# MB9BF46xx register map
File version: 1.0
Registers are 8-bit, read-write, reset 0x0 unless marked. A register's access mark holds for its fields unless they carry their own. Offsets are from the block's base; [hi:lo] are bit positions; 'fields as' and 'values as' point back to an identical list.

## WORKFLASH_IF — peripheral WORKFLASH_IF
Base 0x200E0000
0x00 WFASZR 32-bit reset 0x1
  [0] ASZ
0x04 WFRWTR 32-bit reset 0x4
  [2:0] RWT
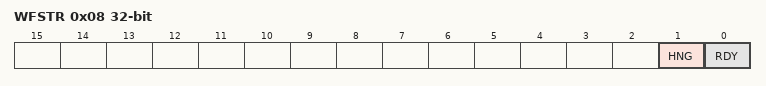
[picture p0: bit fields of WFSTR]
0x08 WFSTR 32-bit ro
  [1] HNG, [0] RDY

## FLASH_IF — peripheral FLASH_IF
Base 0x40000000
0x00 FASZR 32-bit reset 0x2
  [1:0] ASZ
0x04 FRWTR 32-bit reset 0x2
  [1:0] RWT
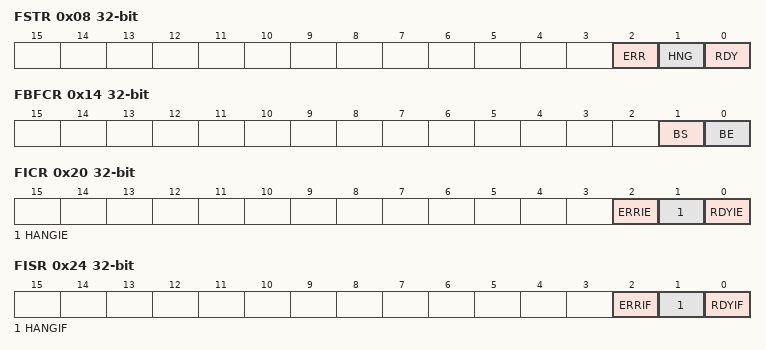
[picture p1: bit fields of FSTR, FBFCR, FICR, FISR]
0x08 FSTR 32-bit ro
  [2] ERR rw, [1] HNG, [0] RDY
0x10 FSYNDN 32-bit
  [2:0] SD
0x14 FBFCR 32-bit
  [1] BS ro, [0] BE
0x20 FICR 32-bit
  [2] ERRIE, [1] HANGIE, [0] RDYIE
0x24 FISR 32-bit
  [2] ERRIF ro, [1] HANGIF ro, [0] RDYIF ro
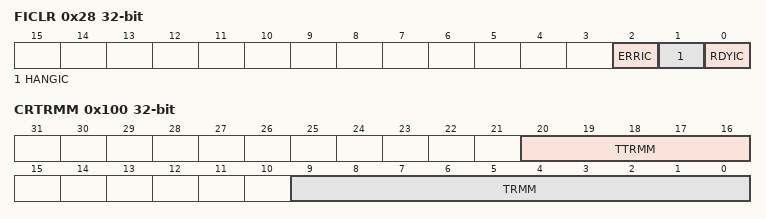
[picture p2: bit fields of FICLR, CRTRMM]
0x28 FICLR 32-bit wo
  [2] ERRIC rw, [1] HANGIC rw, [0] RDYIC rw
0x100 CRTRMM 32-bit ro reset not defined
  [20:16] TTRMM, [9:0] TRMM

## UNIQUE_ID — peripheral UNIQUE_ID
Base 0x40000200
0x00 UIDR0 32-bit ro
  [31:4] UID
0x04 UIDR1 32-bit ro
  [12:0] UID

## ECC_CAPTURE — peripheral ECC_CAPTURE
Base 0x40000300
0x00 FERRAD 32-bit ro
  [22:0] ERRAD

## CRG — peripheral CRG
Base 0x40010000
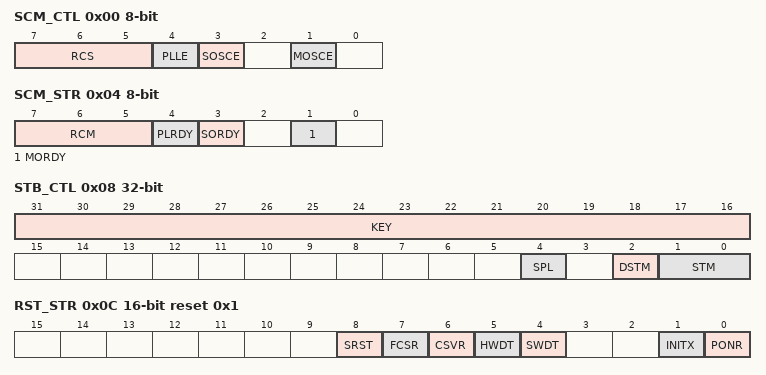
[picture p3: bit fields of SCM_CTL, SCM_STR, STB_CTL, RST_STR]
0x00 SCM_CTL
  [7:5] RCS, [4] PLLE, [3] SOSCE, [1] MOSCE
0x04 SCM_STR ro
  [7:5] RCM, [4] PLRDY, [3] SORDY, [1] MORDY
0x08 STB_CTL 32-bit
  [31:16] KEY, [4] SPL, [2] DSTM, [1:0] STM
0x0C RST_STR 16-bit ro reset 0x1
  [8] SRST, [7] FCSR, [6] CSVR, [5] HWDT, [4] SWDT, [1] INITX, [0] PONR
0x10 BSC_PSR
  [2:0] BSR
0x14 APBC0_PSR
  [1:0] APBC0
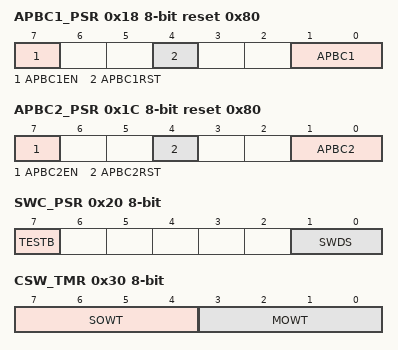
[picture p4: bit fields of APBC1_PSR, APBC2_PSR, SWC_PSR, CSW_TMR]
0x18 APBC1_PSR reset 0x80
  [7] APBC1EN, [4] APBC1RST, [1:0] APBC1
0x1C APBC2_PSR reset 0x80
  [7] APBC2EN, [4] APBC2RST, [1:0] APBC2
0x20 SWC_PSR (reset mask 0x3)
  [7] TESTB, [1:0] SWDS
0x28 TTC_PSR
  [1:0] TTC
0x30 CSW_TMR
  [7:4] SOWT, [3:0] MOWT
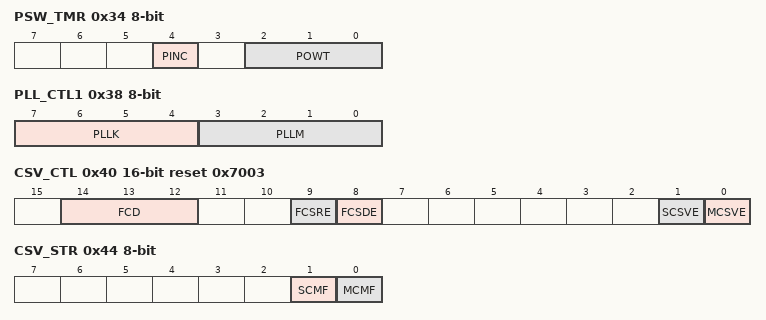
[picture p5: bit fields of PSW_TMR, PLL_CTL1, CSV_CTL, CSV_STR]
0x34 PSW_TMR
  [4] PINC, [2:0] POWT
0x38 PLL_CTL1
  [7:4] PLLK, [3:0] PLLM
0x3C PLL_CTL2
  [5:0] PLLN
0x40 CSV_CTL 16-bit reset 0x7003
  [14:12] FCD, [9] FCSRE, [8] FCSDE, [1] SCSVE, [0] MCSVE
0x44 CSV_STR ro
  [1] SCMF, [0] MCMF
0x48 FCSWH_CTL 16-bit reset 0xFFFF
  [15:0] FWH
0x4C FCSWL_CTL 16-bit
  [15:0] FWL
0x50 FCSWD_CTL 16-bit ro
  [15:0] FWD
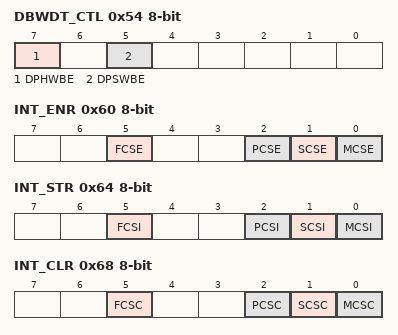
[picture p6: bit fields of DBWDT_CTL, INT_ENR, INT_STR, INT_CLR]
0x54 DBWDT_CTL
  [7] DPHWBE, [5] DPSWBE
0x60 INT_ENR
  [5] FCSE, [2] PCSE, [1] SCSE, [0] MCSE
0x64 INT_STR ro
  [5] FCSI, [2] PCSI, [1] SCSI, [0] MCSI
0x68 INT_CLR wo
  [5] FCSC, [2] PCSC, [1] SCSC, [0] MCSC

## CRTRIM — peripheral CRTRIM
Base 0x4002E000
0x00 MCR_PSR reset 0x1
  [2:0] CSR
0x04 MCR_FTRM 16-bit reset 0x1EF
  [9:0] TRD
0x08 MCR_TTRM reset 0x10
  [4:0] TRT
0x0C MCR_RLR 32-bit reset 0x1
  [31:0] TRMLCK

## SWWDT — peripheral SWWDT
Base 0x40012000
0x00 WDOGLOAD 32-bit reset 0xFFFFFFFF
0x04 WDOGVALUE 32-bit ro reset 0xFFFFFFFF
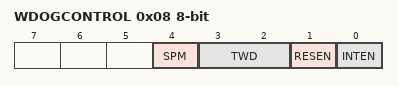
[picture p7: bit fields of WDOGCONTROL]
0x08 WDOGCONTROL
  [4] SPM, [3:2] TWD, [1] RESEN, [0] INTEN
0x0C WDOGINTCLR 32-bit reset 0xFFFFFFFF
0x10 WDOGRIS ro
  [0] RIS
0x18 WDOGSPMC
  [0] TRG ro
0xC00 WDOGLOCK 32-bit

## HWWDT — peripheral HWWDT
Base 0x40011000
0x00 WDG_LDR 32-bit reset 0xFFFF
0x04 WDG_VLR 32-bit ro
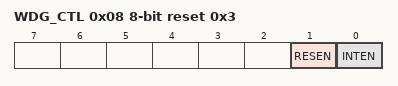
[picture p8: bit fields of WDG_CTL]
0x08 WDG_CTL reset 0x3
  [1] RESEN, [0] INTEN
0x0C WDG_ICL reset 0xFF (reset mask 0x0)
0x10 WDG_RIS ro reset 0xFF (reset mask 0x0)
  [0] RIS
0xC00 WDG_LCK 32-bit reset 0x1

## DTIM — peripheral DTIM
Base 0x40015000
0x00 TIMER1LOAD 32-bit (DualTimer1 view)
0x04 TIMER1VALUE 32-bit ro reset 0xFFFFFFFF
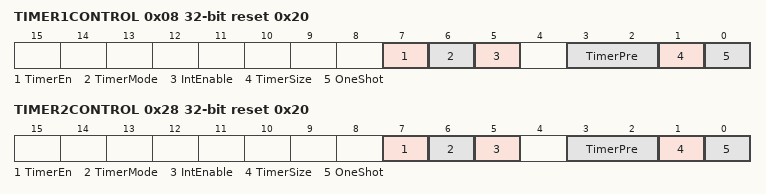
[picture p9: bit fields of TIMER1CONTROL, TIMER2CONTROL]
0x08 TIMER1CONTROL 32-bit reset 0x20
  [7] TimerEn, [6] TimerMode, [5] IntEnable, [3:2] TimerPre, [1] TimerSize, [0] OneShot
0x0C TIMER1INTCLR 32-bit wo reset not defined
0x10 TIMER1RIS 32-bit ro
  [0] TIMER1RIS
0x14 TIMER1MIS 32-bit ro
  [0] TIMER1MIS
0x18 TIMER1BGLOAD 32-bit
0x20 TIMER2LOAD 32-bit
0x24 TIMER2VALUE 32-bit ro reset 0xFFFFFFFF
0x28 TIMER2CONTROL 32-bit reset 0x20
  fields as TIMER1CONTROL
0x2C TIMER2INTCLR 32-bit wo reset not defined
0x30 TIMER2RIS 32-bit ro
  [0] TIMER1RIS
0x34 TIMER2MIS 32-bit ro
  [0] TIMER1MIS
0x38 TIMER2BGLOAD 32-bit

## Notices in the file
Licence Terms
FUJITSU SEMICONDUCTOR LIMITED (gLICENSORh) hereby grants and
you (gLICENSEEh) hereby accept a non transferable, non-exclusive
licence to use and copy the deliverables (gDeliverablesh) solely for
the purpose of; (i) developing LICENSEEfs development tools and
distributing such development tools to third parties; (ii) generating
derivative representations of the Deliverables to develop and debug
software for LICENSORfs targeted devices or device series identified
within the Deliverables, (together the gPurposeh) under the following
terms and conditions:
1. Ownership.
The Deliverables are the property of LICENSOR. LICENSEE acquires no
right, title or interest in the Deliverables other than the licence
rights granted herein.
2. Use.
LICENSEE shall only be permitted to use the Deliverables for the
Purpose. LICENSEE shall not reverse engineer, decompile or
disassemble the Deliverables, in whole or in part.
3. Copies.
All copies of the Deliverables must bear the same notice(s) contained
on the original copies of the Deliverables.
4. No Warranty.
THE DELIVERABLES ARE PROVIDED gAS ISh AND ANY EXPRESS, IMPLIED OR
STATUTORY WARRANTIES, INCLUDING, BUT NOT LIMITED TO, THE IMPLIED
WARRANTIES OF MERCHANTABILITY, SATISFACTORY QUALITY AND FITNESS FOR
A PARTICULAR PURPOSE ARE DISCLAIMED.
IN NO EVENT SHALL LICENSOR BE LIABLE FOR ANY DIRECT, INDIRECT,
INCIDENTAL, SPECIAL, EXEMPLARY, OR CONSEQUENTIAL DAMAGES HOWEVER CAUSED
AND ON ANY THEORY OF LIABILITY, WHETHER IN CONTRACT, STRICT LIABILITY,
OR TORT (INCLUDING NEGLIGENCE OR OTHERWISE) ARISING IN ANY WAY OUT OF
THE USE OF THE DELIVERABLES, EVEN IF ADVISED OF THE POSSIBILITY OF SUCH
DAMAGE.
LICENSEE EXPRESSLY ASSUMES ALL LIABILITIES AND RISKS, FOR USE OR
OPERATION OF THE DELIVERABLES.
5.In the event that LICENSEE receives early access to the Deliverables,
LICENSEE acknowledges and agrees that;
(a) notwithstanding the licence grants above, LICENSEE shall only be
permitted to use the Deliverables solely internally for evaluation and
providing feedback to LICENSOR;
(b) except with respect to the limited licence grants in 5(a), LICENSEE
shall be subject to all of the terms and conditions set out above; and
(c) the Deliverables are confidential information and LICENSEE shall
maintain in confidence the Deliverables and apply security measures no
less stringent than the measures that LICENSEE applies to its own like
information, but not less than a reasonable degree of care, to prevent
unauthorised disclosure and use of the Deliverables.
